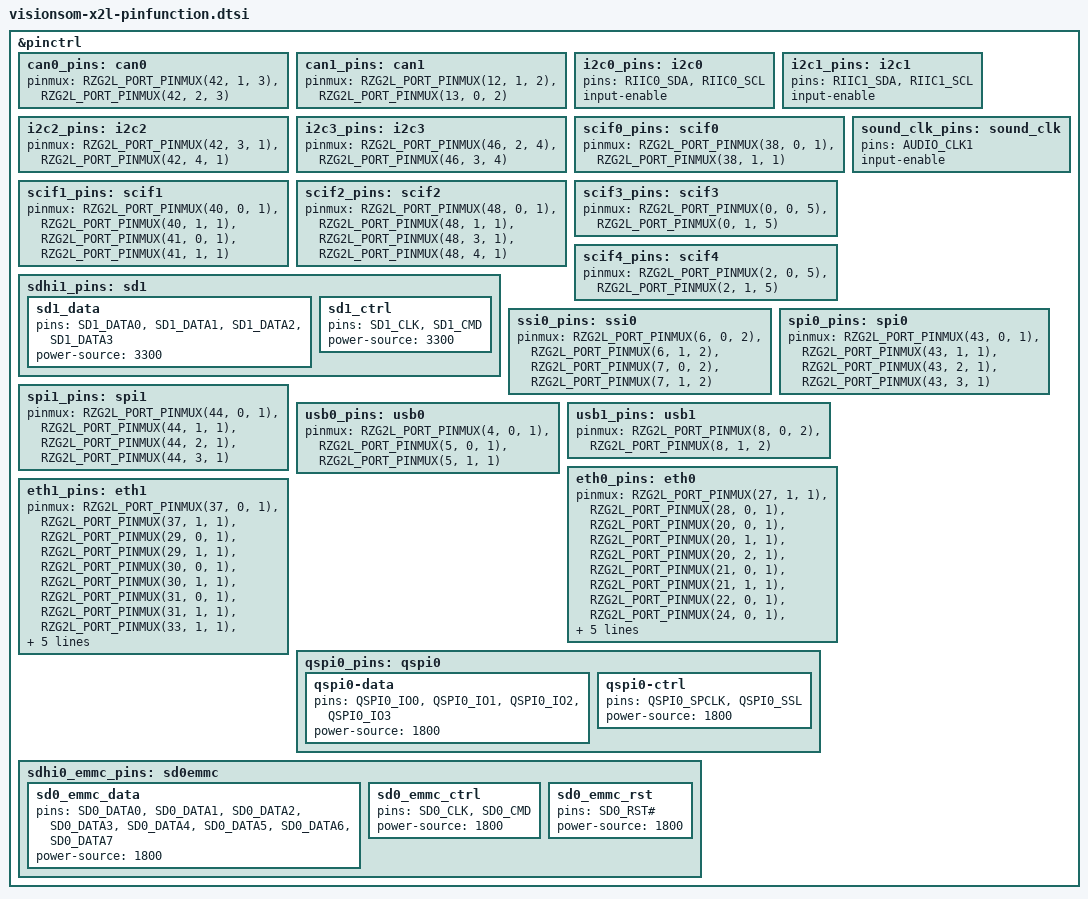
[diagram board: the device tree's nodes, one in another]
// SPDX-License-Identifier: (GPL-2.0-only OR BSD-2-Clause)
/*
 * Device Tree Source for VisionSOM-x2L modules - common pincontrol configuration
 *
 * Copyright (C) 2023 Somlabs
 */

#include <dt-bindings/gpio/gpio.h>
#include <dt-bindings/pinctrl/rzg2l-pinctrl.h>

&pinctrl {
	can0_pins: can0 {
		pinmux = <RZG2L_PORT_PINMUX(42, 1, 3)>, /* TX */
			 <RZG2L_PORT_PINMUX(42, 2, 3)>; /* RX */
	};

	can1_pins: can1 {
		pinmux = <RZG2L_PORT_PINMUX(12, 1, 2)>, /* TX */
			 <RZG2L_PORT_PINMUX(13, 0, 2)>; /* RX */
	};

	i2c0_pins: i2c0 {
		pins = "RIIC0_SDA", "RIIC0_SCL";
		input-enable;
	};

	i2c1_pins: i2c1 {
		pins = "RIIC1_SDA", "RIIC1_SCL";
		input-enable;
	};

	i2c2_pins: i2c2 {
		pinmux = <RZG2L_PORT_PINMUX(42, 3, 1)>, /* SDA */
			 <RZG2L_PORT_PINMUX(42, 4, 1)>; /* SCL */
	};

	i2c3_pins: i2c3 {
		pinmux = <RZG2L_PORT_PINMUX(46, 2, 4)>, /* SDA */
			 <RZG2L_PORT_PINMUX(46, 3, 4)>; /* SCL */
	};

	scif0_pins: scif0 {
		pinmux = <RZG2L_PORT_PINMUX(38, 0, 1)>,	/* TxD */
			 <RZG2L_PORT_PINMUX(38, 1, 1)>;	/* RxD */
	};

	scif1_pins: scif1 {
		pinmux = <RZG2L_PORT_PINMUX(40, 0, 1)>, /* TxD */
			 <RZG2L_PORT_PINMUX(40, 1, 1)>, /* RxD */
			 <RZG2L_PORT_PINMUX(41, 0, 1)>, /* CTS# */
			 <RZG2L_PORT_PINMUX(41, 1, 1)>; /* RTS# */
	};

	scif2_pins: scif2 {
		pinmux = <RZG2L_PORT_PINMUX(48, 0, 1)>, /* TxD */
			 <RZG2L_PORT_PINMUX(48, 1, 1)>, /* RxD */
			 <RZG2L_PORT_PINMUX(48, 3, 1)>, /* CTS# */
			 <RZG2L_PORT_PINMUX(48, 4, 1)>; /* RTS# */
	};

	scif3_pins: scif3 {
		pinmux = <RZG2L_PORT_PINMUX(0, 0, 5)>,	/* TxD */
			 <RZG2L_PORT_PINMUX(0, 1, 5)>;	/* RxD */
	};

	scif4_pins: scif4 {
		pinmux = <RZG2L_PORT_PINMUX(2, 0, 5)>,	/* TxD */
			 <RZG2L_PORT_PINMUX(2, 1, 5)>;	/* RxD */
	};

	sdhi1_pins: sd1 {
		sd1_data {
			pins = "SD1_DATA0", "SD1_DATA1", "SD1_DATA2", "SD1_DATA3";
			power-source = <3300>;
		};

		sd1_ctrl {
			pins = "SD1_CLK", "SD1_CMD";
			power-source = <3300>;
		};
	};

	ssi0_pins: ssi0 {
		pinmux = <RZG2L_PORT_PINMUX(6, 0, 2)>, /* BCK */
			 <RZG2L_PORT_PINMUX(6, 1, 2)>, /* RCK */
			 <RZG2L_PORT_PINMUX(7, 0, 2)>, /* TXD */
			 <RZG2L_PORT_PINMUX(7, 1, 2)>; /* RXD */
	};

	sound_clk_pins: sound_clk {
		pins = "AUDIO_CLK1";
		input-enable;
	};

	spi0_pins: spi0 {
		pinmux = <RZG2L_PORT_PINMUX(43, 0, 1)>, /* CK */
			 <RZG2L_PORT_PINMUX(43, 1, 1)>, /* MOSI */
			 <RZG2L_PORT_PINMUX(43, 2, 1)>, /* MISO */
			 <RZG2L_PORT_PINMUX(43, 3, 1)>; /* SSL */
	};

	spi1_pins: spi1 {
		pinmux = <RZG2L_PORT_PINMUX(44, 0, 1)>, /* CK */
			 <RZG2L_PORT_PINMUX(44, 1, 1)>, /* MOSI */
			 <RZG2L_PORT_PINMUX(44, 2, 1)>, /* MISO */
			 <RZG2L_PORT_PINMUX(44, 3, 1)>; /* SSL */
	};

	usb0_pins: usb0 {
		pinmux = <RZG2L_PORT_PINMUX(4, 0, 1)>, /* VBUS */
			 <RZG2L_PORT_PINMUX(5, 0, 1)>, /* OVC */
			 <RZG2L_PORT_PINMUX(5, 1, 1)>; /* OTG_ID */
	};

	usb1_pins: usb1 {
		pinmux = <RZG2L_PORT_PINMUX(8, 0, 2)>, /* VBUS */
			 <RZG2L_PORT_PINMUX(8, 1, 2)>; /* OVC */
	};

	eth0_pins: eth0 {
		pinmux =
			 <RZG2L_PORT_PINMUX(27, 1, 1)>, /* ET0_MDC */
			 <RZG2L_PORT_PINMUX(28, 0, 1)>, /* ET0_MDIO */
			 <RZG2L_PORT_PINMUX(20, 0, 1)>, /* ET0_TXC */
			 <RZG2L_PORT_PINMUX(20, 1, 1)>, /* ET0_TX_CTL */
			 <RZG2L_PORT_PINMUX(20, 2, 1)>, /* ET0_TXD0 */
			 <RZG2L_PORT_PINMUX(21, 0, 1)>, /* ET0_TXD1 */
			 <RZG2L_PORT_PINMUX(21, 1, 1)>, /* ET0_TXD2 */
			 <RZG2L_PORT_PINMUX(22, 0, 1)>, /* ET0_TXD3 */
			 <RZG2L_PORT_PINMUX(24, 0, 1)>, /* ET0_RXC */
			 <RZG2L_PORT_PINMUX(24, 1, 1)>, /* ET0_RX_CTL */
			 <RZG2L_PORT_PINMUX(25, 0, 1)>, /* ET0_RXD0 */
			 <RZG2L_PORT_PINMUX(25, 1, 1)>, /* ET0_RXD1 */
			 <RZG2L_PORT_PINMUX(26, 0, 1)>, /* ET0_RXD2 */
			 <RZG2L_PORT_PINMUX(26, 1, 1)>; /* ET0_RXD3 */
	};

	eth1_pins: eth1 {
		pinmux =
			 <RZG2L_PORT_PINMUX(37, 0, 1)>, /* ET1_MDC */
			 <RZG2L_PORT_PINMUX(37, 1, 1)>, /* ET1_MDIO */
			 <RZG2L_PORT_PINMUX(29, 0, 1)>, /* ET1_TXC */
			 <RZG2L_PORT_PINMUX(29, 1, 1)>, /* ET1_TX_CTL */
			 <RZG2L_PORT_PINMUX(30, 0, 1)>, /* ET1_TXD0 */
			 <RZG2L_PORT_PINMUX(30, 1, 1)>, /* ET1_TXD1 */
			 <RZG2L_PORT_PINMUX(31, 0, 1)>, /* ET1_TXD2 */
			 <RZG2L_PORT_PINMUX(31, 1, 1)>, /* ET1_TXD3 */
			 <RZG2L_PORT_PINMUX(33, 1, 1)>, /* ET1_RXC */
			 <RZG2L_PORT_PINMUX(34, 0, 1)>, /* ET1_RX_CTL */
			 <RZG2L_PORT_PINMUX(34, 1, 1)>, /* ET1_RXD0 */
			 <RZG2L_PORT_PINMUX(35, 0, 1)>, /* ET1_RXD1 */
			 <RZG2L_PORT_PINMUX(35, 1, 1)>, /* ET1_RXD2 */
			 <RZG2L_PORT_PINMUX(36, 0, 1)>; /* ET1_RXD3 */
	};

	qspi0_pins: qspi0 {
		qspi0-data {
			pins = "QSPI0_IO0", "QSPI0_IO1", "QSPI0_IO2", "QSPI0_IO3";
			power-source = <1800>;
		};

		qspi0-ctrl {
			pins = "QSPI0_SPCLK", "QSPI0_SSL";
			power-source = <1800>;
		};
	};

	sdhi0_emmc_pins: sd0emmc {
		sd0_emmc_data {
			pins = "SD0_DATA0", "SD0_DATA1", "SD0_DATA2", "SD0_DATA3",
			       "SD0_DATA4", "SD0_DATA5", "SD0_DATA6", "SD0_DATA7";
			power-source = <1800>;
		};

		sd0_emmc_ctrl {
			pins = "SD0_CLK", "SD0_CMD";
			power-source = <1800>;
		};

		sd0_emmc_rst {
			pins = "SD0_RST#";
			power-source = <1800>;
		};
	};

};
